# ESP32-P4-LP register map
Vendor: ESPRESSIF SYSTEMS (SHANGHAI) CO., LTD.; Series: ESP32 P-Series; File version: 3
CPU: RV32IMAC r0p0, little endian, no MPU, no FPU, 0 interrupt priority bits
Address unit: 32 bits
Registers are 32-bit, read-write, reset 0x0 unless marked. A register's access mark holds for its fields unless they carry their own. Offsets are from the block's base; [hi:lo] are bit positions; lines under a group give offsets from that group; {n}, {i} and the like mark numbered series.

## LP_SYS — LP_SYS Peripheral
Base 0x50110000
0x00 LP_SYS_VER_DATE reset 0x20250214 — need_des
  [31:0] VER_DATE
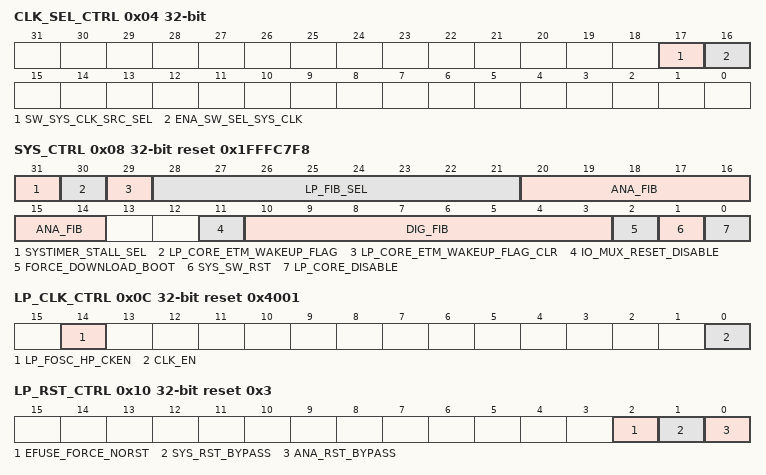
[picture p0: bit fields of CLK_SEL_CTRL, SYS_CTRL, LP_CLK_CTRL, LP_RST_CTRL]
0x04 CLK_SEL_CTRL — need_des
  [17] SW_SYS_CLK_SRC_SEL — reserved
  [16] ENA_SW_SEL_SYS_CLK — reserved
0x08 SYS_CTRL access per field reset 0x1FFFC7F8 — need_des
  [31] SYSTIMER_STALL_SEL rw — 0: use systimer_stall signal from hp_core0, 1: use systimer_stall signal from hp_core1
  [30] LP_CORE_ETM_WAKEUP_FLAG rw — need_des
  [29] LP_CORE_ETM_WAKEUP_FLAG_CLR wo — need_des
  [28:21] LP_FIB_SEL rw — need_des
  [20:14] ANA_FIB ro — need_des
  [11] IO_MUX_RESET_DISABLE rw — reset disable bit for LP IOMUX
  [10:3] DIG_FIB rw — need_des
  [2] FORCE_DOWNLOAD_BOOT rw — need_des
  [1] SYS_SW_RST wo — digital system software reset bit
  [0] LP_CORE_DISABLE rw — lp cpu disable
0x0C LP_CLK_CTRL reset 0x4001 — need_des
  [14] LP_FOSC_HP_CKEN — reserved
  [0] CLK_EN — need_des
0x10 LP_RST_CTRL reset 0x3 — need_des
  [2] EFUSE_FORCE_NORST — efuse force no reset control
  [1] SYS_RST_BYPASS — system source reset bypass : software reset,hp wdt,lp wdt,efuse
  [0] ANA_RST_BYPASS — analog source reset bypass : wdt,brown out,super wdt,glitch
0x18 LP_CORE_BOOT_ADDR reset 0x50100000 — need_des
  [31:0] LP_CPU_BOOT_ADDR
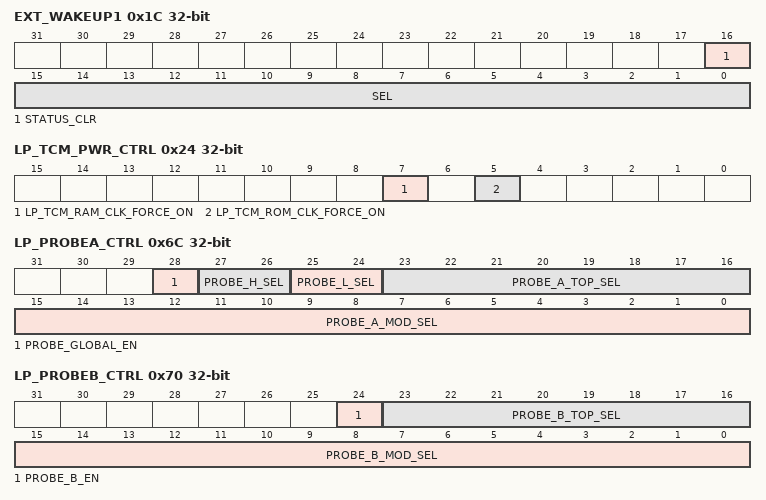
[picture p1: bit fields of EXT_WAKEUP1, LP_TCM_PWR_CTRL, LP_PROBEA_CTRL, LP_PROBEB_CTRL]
0x1C EXT_WAKEUP1 access per field — need_des
  [16] STATUS_CLR wo — clear ext wakeup1 status
  [15:0] SEL rw — Bitmap to select RTC pads for ext wakeup1
0x20 EXT_WAKEUP1_STATUS ro — need_des
  [15:0] EXT_WAKEUP1_STATUS
0x24 LP_TCM_PWR_CTRL — need_des
  [7] LP_TCM_RAM_CLK_FORCE_ON — need_des
  [5] LP_TCM_ROM_CLK_FORCE_ON — need_des
0x28 BOOT_ADDR_HP_LP — need_des
{0x2C+4i} LP_STORE{i} (i=0..15) — need_des
  [31:0] LP_SCRATCH{i}
0x6C LP_PROBEA_CTRL — need_des
  [28] PROBE_GLOBAL_EN — need_des
  [27:26] PROBE_H_SEL — need_des
  [25:24] PROBE_L_SEL — need_des
  [23:16] PROBE_A_TOP_SEL — need_des
  [15:0] PROBE_A_MOD_SEL — need_des
0x70 LP_PROBEB_CTRL — need_des
  [24] PROBE_B_EN — need_des
  [23:16] PROBE_B_TOP_SEL — need_des
  [15:0] PROBE_B_MOD_SEL — need_des
0x74 LP_PROBE_OUT ro — need_des
  [31:0] PROBE_TOP_OUT
0x9C F2S_APB_BRG_CNTL — need_des
  [0] F2S_APB_POSTW_EN — reserved
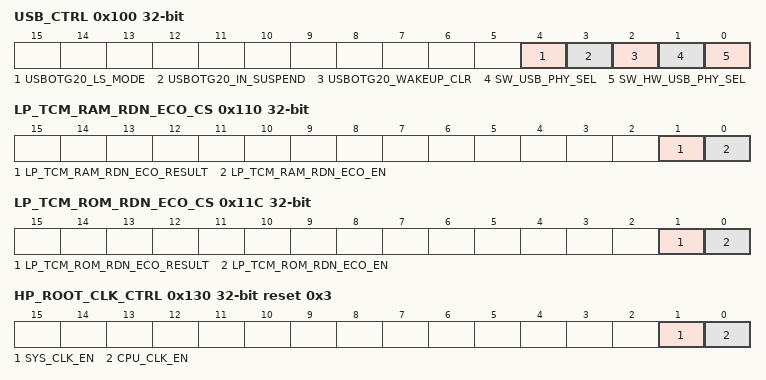
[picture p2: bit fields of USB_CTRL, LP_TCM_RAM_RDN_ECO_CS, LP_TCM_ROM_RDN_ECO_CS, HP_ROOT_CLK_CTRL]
0x100 USB_CTRL access per field — need_des
  [4] USBOTG20_LS_MODE rw — indicate current mode of usb otg2.0.
  [3] USBOTG20_IN_SUSPEND rw — indicate usb otg2.0 is in suspend state.
  [2] USBOTG20_WAKEUP_CLR wo — clear usb wakeup to PMU.
  [1] SW_USB_PHY_SEL rw — need_des
  [0] SW_HW_USB_PHY_SEL rw — need_des
0x10C ANA_XPD_PAD_GROUP reset 0xFF — need_des
  [7:0] ANA_REG_XPD_PAD_GROUP — Set 1 to power up pad group
0x110 LP_TCM_RAM_RDN_ECO_CS access per field — need_des
  [1] LP_TCM_RAM_RDN_ECO_RESULT ro — need_des
  [0] LP_TCM_RAM_RDN_ECO_EN rw — need_des
0x114 LP_TCM_RAM_RDN_ECO_LOW — need_des
0x118 LP_TCM_RAM_RDN_ECO_HIGH reset 0xFFFFFFFF — need_des
0x11C LP_TCM_ROM_RDN_ECO_CS access per field — need_des
  [1] LP_TCM_ROM_RDN_ECO_RESULT ro — need_des
  [0] LP_TCM_ROM_RDN_ECO_EN rw — need_des
0x120 LP_TCM_ROM_RDN_ECO_LOW — need_des
0x124 LP_TCM_ROM_RDN_ECO_HIGH reset 0xFFFFFFFF — need_des
0x130 HP_ROOT_CLK_CTRL reset 0x3 — need_des
  [1] SYS_CLK_EN — clock gate enable for hp sys root 480M clk
  [0] CPU_CLK_EN — clock gate enable for hp cpu root 400M clk
0x138 LP_PMU_RDN_ECO_LOW — need_des
  [31:0] PMU_RDN_ECO_LOW
0x13C LP_PMU_RDN_ECO_HIGH reset 0xFFFFFFFF — need_des
  [31:0] PMU_RDN_ECO_HIGH
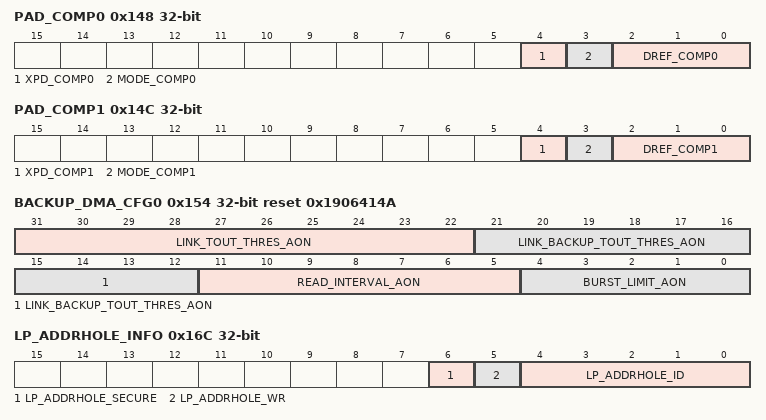
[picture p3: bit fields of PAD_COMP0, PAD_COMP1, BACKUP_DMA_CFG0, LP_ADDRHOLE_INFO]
0x148 PAD_COMP0 — need_des
  [4] XPD_COMP0 — pad comp xpd
  [3] MODE_COMP0 — pad comp mode
  [2:0] DREF_COMP0 — pad comp dref
0x14C PAD_COMP1 — need_des
  [4] XPD_COMP1 — pad comp xpd
  [3] MODE_COMP1 — pad comp mode
  [2:0] DREF_COMP1 — pad comp dref
0x154 BACKUP_DMA_CFG0 reset 0x1906414A — need_des
  [31:22] LINK_TOUT_THRES_AON — need_des
  [21:12] LINK_BACKUP_TOUT_THRES_AON — need_des
  [11:5] READ_INTERVAL_AON — need_des
  [4:0] BURST_LIMIT_AON — need_des
0x158 BACKUP_DMA_CFG1 — need_des
  [31] AON_BYPASS
0x15C BACKUP_DMA_CFG2 — need_des
  [31:0] LINK_ADDR_AON
0x164 BOOT_ADDR_HP_CORE1 — need_des
0x168 LP_ADDRHOLE_ADDR ro — need_des
0x16C LP_ADDRHOLE_INFO ro — need_des
  [6] LP_ADDRHOLE_SECURE — 1: illegal address access, 0: access without permission
  [5] LP_ADDRHOLE_WR — 1:write trans, 0: read trans.
  [4:0] LP_ADDRHOLE_ID — master id: 5'h0: hp core0, 5'h1:hp core1, 5'h2:lp core, 5'h3:usb otg11, 5'h4: regdma, 5'h5: gmac, 5'h5 sdmmc, 5'h7: usbotg20, 5'h8: trace0, 5'h9: trace1, 5'ha tcm monitor, 5'hb: l2mem monitor. 5'h10~5'h1f: ahb pdma.
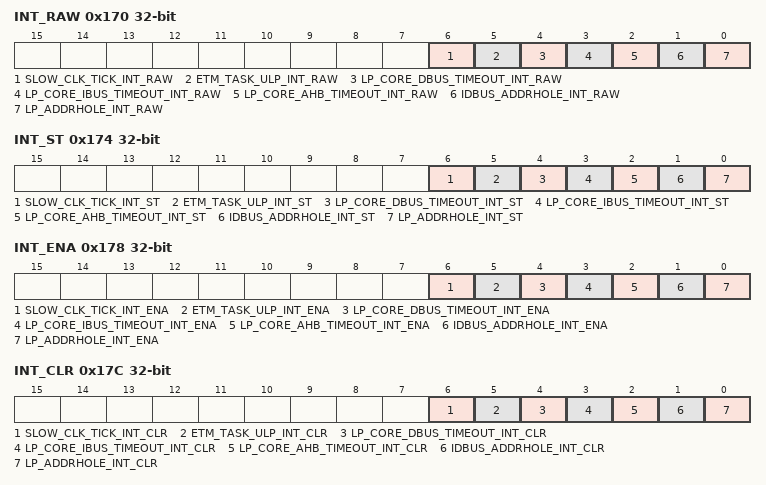
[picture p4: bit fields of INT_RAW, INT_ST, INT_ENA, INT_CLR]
0x170 INT_RAW ro — raw interrupt register
  [6] SLOW_CLK_TICK_INT_RAW — the raw interrupt status of slow_clk_tick
  [5] ETM_TASK_ULP_INT_RAW — the raw interrupt status of etm task ulp
  [4] LP_CORE_DBUS_TIMEOUT_INT_RAW — the raw interrupt status of lp core dbus timeout
  [3] LP_CORE_IBUS_TIMEOUT_INT_RAW — the raw interrupt status of lp core ibus timeout
  [2] LP_CORE_AHB_TIMEOUT_INT_RAW — the raw interrupt status of lp core ahb bus timeout
  [1] IDBUS_ADDRHOLE_INT_RAW — the raw interrupt status of idbus addrhole(only for lp cpu ibus and dbus)
  [0] LP_ADDRHOLE_INT_RAW — the raw interrupt status of lp addrhole(for lp peri and lp ram tee apm, and lp matrix default slave)
0x174 INT_ST ro — masked interrupt register
  [6] SLOW_CLK_TICK_INT_ST — the masked interrupt status of slow_clk_tick
  [5] ETM_TASK_ULP_INT_ST — the masked interrupt status of etm task ulp
  [4] LP_CORE_DBUS_TIMEOUT_INT_ST — the masked interrupt status of lp core dbus timeout
  [3] LP_CORE_IBUS_TIMEOUT_INT_ST — the masked interrupt status of lp core ibus timeout
  [2] LP_CORE_AHB_TIMEOUT_INT_ST — the masked interrupt status of lp core ahb bus timeout
  [1] IDBUS_ADDRHOLE_INT_ST — the masked interrupt status of idbus addrhole(only for lp cpu ibus and dbus)
  [0] LP_ADDRHOLE_INT_ST — the masked interrupt status of lp addrhole (for lp peri and lp ram tee apm, and lp matrix default slave)
0x178 INT_ENA — masked interrupt register
  [6] SLOW_CLK_TICK_INT_ENA — Write 1 to enable slow_clk_tick int
  [5] ETM_TASK_ULP_INT_ENA — Write 1 to enable etm task ulp int
  [4] LP_CORE_DBUS_TIMEOUT_INT_ENA — Write 1 to enable lp_core_dbus_timeout int
  [3] LP_CORE_IBUS_TIMEOUT_INT_ENA — Write 1 to enable lp_core_ibus_timeout int
  [2] LP_CORE_AHB_TIMEOUT_INT_ENA — Write 1 to enable lp_core_ahb_timeout int
  [1] IDBUS_ADDRHOLE_INT_ENA — Write 1 to enable idbus addrhole int
  [0] LP_ADDRHOLE_INT_ENA — Write 1 to enable lp addrhole int
0x17C INT_CLR wo — interrupt clear register
  [6] SLOW_CLK_TICK_INT_CLR — Write 1 to clear slow_clk_tick int
  [5] ETM_TASK_ULP_INT_CLR — Write 1 to clear etm tasl ulp int
  [4] LP_CORE_DBUS_TIMEOUT_INT_CLR — Write 1 to clear lp_core_dbus_timeout int
  [3] LP_CORE_IBUS_TIMEOUT_INT_CLR — Write 1 to clear lp_core_ibus_timeout int
  [2] LP_CORE_AHB_TIMEOUT_INT_CLR — Write 1 to clear lp_core_ahb_timeout int
  [1] IDBUS_ADDRHOLE_INT_CLR — write 1 to clear idbus addrhole int
  [0] LP_ADDRHOLE_INT_CLR — write 1 to clear lp addrhole int
0x180 HP_MEM_AUX_CTRL reset 0x2070 — need_des
0x184 LP_MEM_AUX_CTRL reset 0x2070 — need_des
0x188 HP_ROM_AUX_CTRL reset 0x70 — need_des
0x18C LP_ROM_AUX_CTRL reset 0x70 — need_des
0x190 LP_CPU_DBG_PC ro — need_des
0x194 LP_CPU_EXC_PC ro — need_des
0x198 IDBUS_ADDRHOLE_ADDR ro — need_des
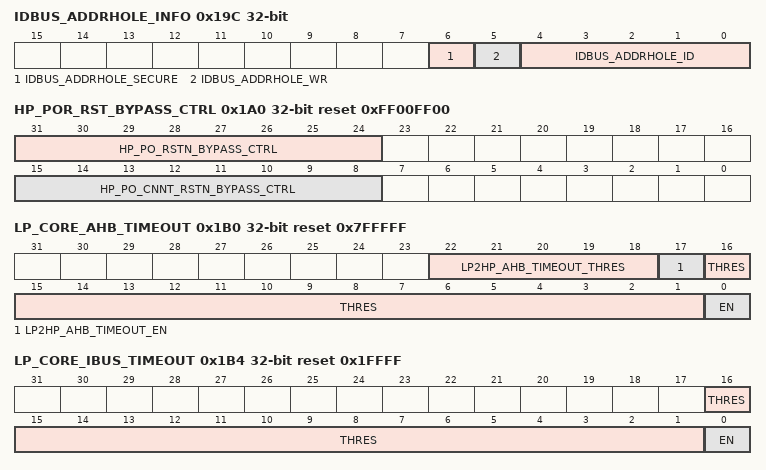
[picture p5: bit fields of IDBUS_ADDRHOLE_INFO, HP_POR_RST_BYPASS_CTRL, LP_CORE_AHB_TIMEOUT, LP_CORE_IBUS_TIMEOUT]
0x19C IDBUS_ADDRHOLE_INFO ro — need_des
  [6] IDBUS_ADDRHOLE_SECURE — need_des
  [5] IDBUS_ADDRHOLE_WR — need_des
  [4:0] IDBUS_ADDRHOLE_ID — need_des
0x1A0 HP_POR_RST_BYPASS_CTRL reset 0xFF00FF00 — need_des
  [31:24] HP_PO_RSTN_BYPASS_CTRL — [31] 1'b1: po_rstn bypass sys_sw_rstn [30] 1'b1: po_rstn bypass hp_wdt_sys_rstn [29] 1'b1: po_rstn bypass hp_cpu_intrusion_rstn [28] 1'b1: po_rstn bypass hp_sdio_sys_rstn [27] 1'b1: po_rstn bypass usb_jtag_chip_rst [26] 1'b1: po_rstn bypass usb_uart_chip_rst [25] 1'b1: po_rstn bypass lp_wdt_hp_sys_rstn [24] 1'b1: po_rstn bypass efuse_err_rstn
  [15:8] HP_PO_CNNT_RSTN_BYPASS_CTRL — [15] 1'b1: po_cnnt_rstn bypass sys_sw_rstn [14] 1'b1: po_cnnt_rstn bypass hp_wdt_sys_rstn [13] 1'b1: po_cnnt_rstn bypass hp_cpu_intrusion_rstn [12] 1'b1: po_cnnt_rstn bypass hp_sdio_sys_rstn [11] 1'b1: po_cnnt_rstn bypass usb_jtag_chip_rst [10] 1'b1: po_cnnt_rstn bypass usb_uart_chip_rst [9] 1'b1: po_cnnt_rstn bypass lp_wdt_hp_sys_rstn [8] 1'b1: po_cnnt_rstn bypass efuse_err_rstn
0x1A4 RNG_DATA ro
  [31:0] RND_DATA — result of rng output
0x1B0 LP_CORE_AHB_TIMEOUT reset 0x7FFFFF — need_des
  [22:18] LP2HP_AHB_TIMEOUT_THRES — This field used to set lp2hp ahb bus timeout threshold
  [17] LP2HP_AHB_TIMEOUT_EN — set this field to 1 to enable lp2hp ahb timeout handle
  [16:1] THRES — This field used to set lp core ahb bus timeout threshold
  [0] EN — set this field to 1 to enable lp core ahb timeout handle
0x1B4 LP_CORE_IBUS_TIMEOUT reset 0x1FFFF — need_des
  [16:1] THRES — This field used to set lp core ibus timeout threshold
  [0] EN — set this field to 1 to enable lp core ibus timeout handle
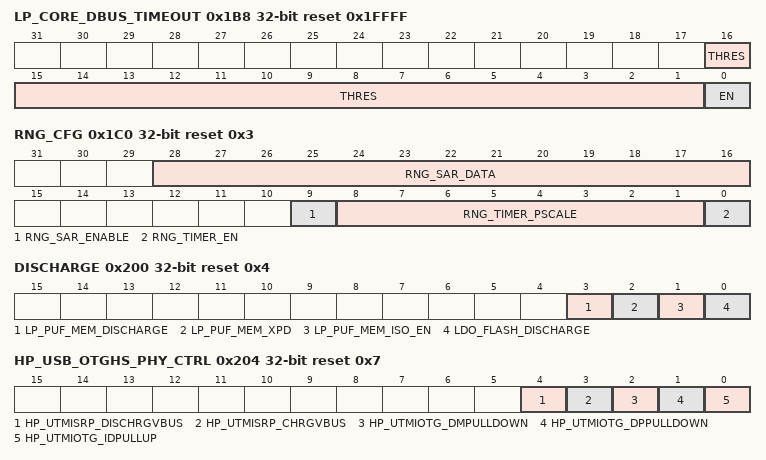
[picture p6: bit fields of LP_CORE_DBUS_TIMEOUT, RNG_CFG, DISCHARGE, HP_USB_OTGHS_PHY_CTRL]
0x1B8 LP_CORE_DBUS_TIMEOUT reset 0x1FFFF — need_des
  [16:1] THRES — This field used to set lp core dbus timeout threshold
  [0] EN — set this field to 1 to enable lp core dbus timeout handle
0x1BC LP_CORE_ERR_RESP_DIS — need_des
  [2:0] LP_CORE_ERR_RESP_DIS — Set bit0 to disable ibus err resp;Set bit1 to disable dbus err resp; Set bit 2 to disable ahb err resp.
0x1C0 RNG_CFG access per field reset 0x3
  [28:16] RNG_SAR_DATA ro — debug rng sar sample cnt
  [9] RNG_SAR_ENABLE rw — enable rng_saradc
  [8:1] RNG_TIMER_PSCALE rw — configure ng timer pscale
  [0] RNG_TIMER_EN rw — enable rng timer
0x1C4 PAD_RTC_HOLD_CTRL0 — enable pad hold ctrl
  [31:0] PAD_RTC_HOLD_CTRL0 — Set 1 to hold pad 0-31 status
0x1C8 PAD_RTC_HOLD_CTRL1 — enable pad hold ctrl
  [24:0] PAD_RTC_HOLD_CTRL1 — Set 1 to hold pad 32-56 status
0x1CC DED_PAD_RTC_HOLD_CTRL — enable pad hold ctrl
  [25:0] DED_PAD_RTC_HOLD_CTRL — Set bit0-5 to hold flash pad status. Set bit6-25 to hold psram pad status.
0x200 DISCHARGE reset 0x4 — pufmem / ldo flash power discharge control
  [3] LP_PUF_MEM_DISCHARGE — Set this bit to discharge lp puf mem.
  [2] LP_PUF_MEM_XPD — Set this bit to discharge lp puf mem.
  [1] LP_PUF_MEM_ISO_EN — Set this bit to discharge lp puf mem.
  [0] LDO_FLASH_DISCHARGE — Set this bit to discharge ldo flash.
0x204 HP_USB_OTGHS_PHY_CTRL reset 0x7 — Usb otg2.0 PHY control register
  [4] HP_UTMISRP_DISCHRGVBUS — Set this bit to discharge USB OTG2.0 PHY vbus
  [3] HP_UTMISRP_CHRGVBUS — Set this bit to charge USB OTG2.0 PHY vbus
  [2] HP_UTMIOTG_DMPULLDOWN — Set this bit to pull down USB OTG2.0 PHY dm
  [1] HP_UTMIOTG_DPPULLDOWN — Set this bit to pull down USB OTG2.0 PHY dp
  [0] HP_UTMIOTG_IDPULLUP — Set this bit to pull up USB OTG2.0 PHY id
